CM_ "AUTOGENERATED FILE, DO NOT EDIT";

CM_ "rivian_mando_front_radar.dbc starts here";

VERSION ""

NS_ :

BS_:

BU_: XXX

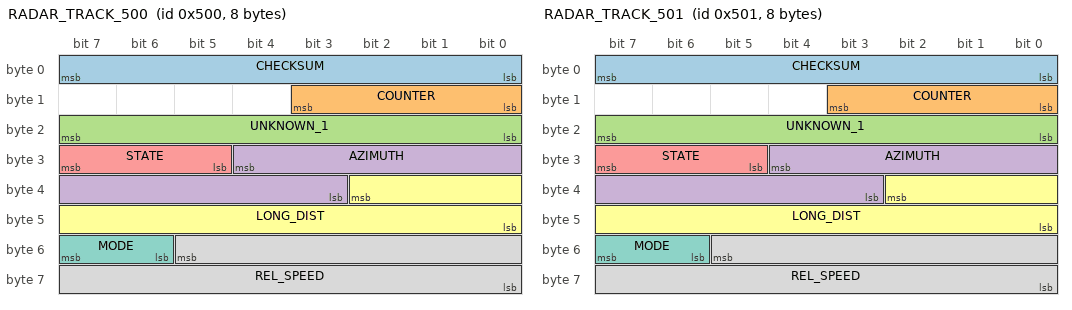
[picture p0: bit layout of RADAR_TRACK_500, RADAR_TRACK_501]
BO_ 1280 RADAR_TRACK_500: 8 RADAR
 SG_ CHECKSUM : 0|8@1+ (1,0) [0|255] "" XXX
 SG_ COUNTER : 11|4@0+ (1,0) [0|15] "" XXX
 SG_ UNKNOWN_1 : 23|8@0- (1,0) [-128|127] "" XXX
 SG_ AZIMUTH : 28|10@0- (0.1,0) [-51.2|51.1] "" XXX
 SG_ STATE : 31|3@0+ (1,0) [0|7] "" XXX
 SG_ LONG_DIST : 34|11@0+ (0.1,0) [0|204.7] "" XXX
 SG_ MODE : 55|2@0+ (1,0) [0|3] "" XXX
 SG_ REL_SPEED : 53|14@0- (0.01,0) [-81.92|81.92] "m/s" XXX

BO_ 1281 RADAR_TRACK_501: 8 RADAR
 SG_ CHECKSUM : 0|8@1+ (1,0) [0|255] "" XXX
 SG_ COUNTER : 11|4@0+ (1,0) [0|15] "" XXX
 SG_ UNKNOWN_1 : 23|8@0- (1,0) [-128|127] "" XXX
 SG_ AZIMUTH : 28|10@0- (0.1,0) [-51.2|51.1] "" XXX
 SG_ STATE : 31|3@0+ (1,0) [0|7] "" XXX
 SG_ LONG_DIST : 34|11@0+ (0.1,0) [0|204.7] "" XXX
 SG_ MODE : 55|2@0+ (1,0) [0|3] "" XXX
 SG_ REL_SPEED : 53|14@0- (0.01,0) [-81.92|81.92] "m/s" XXX

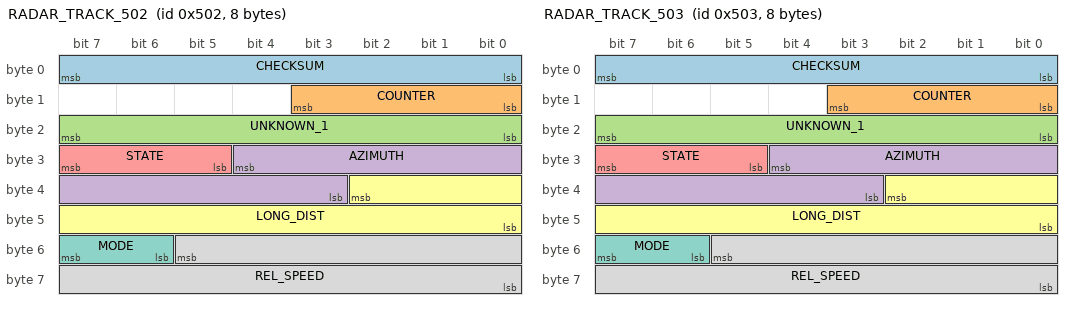
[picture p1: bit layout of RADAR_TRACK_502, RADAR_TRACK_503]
BO_ 1282 RADAR_TRACK_502: 8 RADAR
 SG_ CHECKSUM : 0|8@1+ (1,0) [0|255] "" XXX
 SG_ COUNTER : 11|4@0+ (1,0) [0|15] "" XXX
 SG_ UNKNOWN_1 : 23|8@0- (1,0) [-128|127] "" XXX
 SG_ AZIMUTH : 28|10@0- (0.1,0) [-51.2|51.1] "" XXX
 SG_ STATE : 31|3@0+ (1,0) [0|7] "" XXX
 SG_ LONG_DIST : 34|11@0+ (0.1,0) [0|204.7] "" XXX
 SG_ MODE : 55|2@0+ (1,0) [0|3] "" XXX
 SG_ REL_SPEED : 53|14@0- (0.01,0) [-81.92|81.92] "m/s" XXX

BO_ 1283 RADAR_TRACK_503: 8 RADAR
 SG_ CHECKSUM : 0|8@1+ (1,0) [0|255] "" XXX
 SG_ COUNTER : 11|4@0+ (1,0) [0|15] "" XXX
 SG_ UNKNOWN_1 : 23|8@0- (1,0) [-128|127] "" XXX
 SG_ AZIMUTH : 28|10@0- (0.1,0) [-51.2|51.1] "" XXX
 SG_ STATE : 31|3@0+ (1,0) [0|7] "" XXX
 SG_ LONG_DIST : 34|11@0+ (0.1,0) [0|204.7] "" XXX
 SG_ MODE : 55|2@0+ (1,0) [0|3] "" XXX
 SG_ REL_SPEED : 53|14@0- (0.01,0) [-81.92|81.92] "m/s" XXX

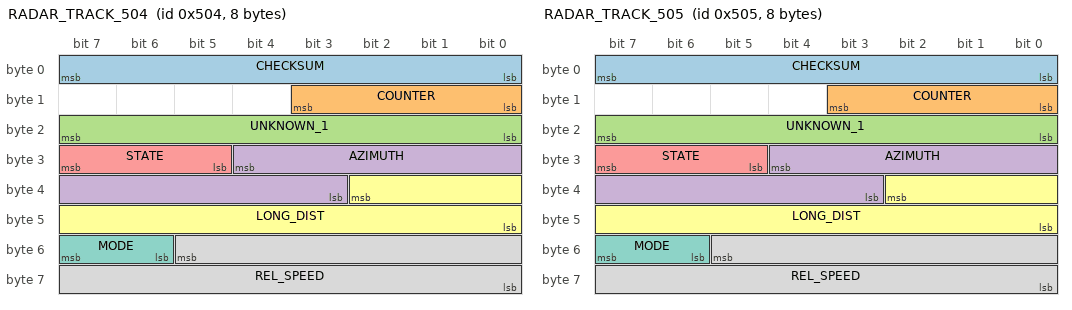
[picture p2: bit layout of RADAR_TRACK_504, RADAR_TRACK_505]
BO_ 1284 RADAR_TRACK_504: 8 RADAR
 SG_ CHECKSUM : 0|8@1+ (1,0) [0|255] "" XXX
 SG_ COUNTER : 11|4@0+ (1,0) [0|15] "" XXX
 SG_ UNKNOWN_1 : 23|8@0- (1,0) [-128|127] "" XXX
 SG_ AZIMUTH : 28|10@0- (0.1,0) [-51.2|51.1] "" XXX
 SG_ STATE : 31|3@0+ (1,0) [0|7] "" XXX
 SG_ LONG_DIST : 34|11@0+ (0.1,0) [0|204.7] "" XXX
 SG_ MODE : 55|2@0+ (1,0) [0|3] "" XXX
 SG_ REL_SPEED : 53|14@0- (0.01,0) [-81.92|81.92] "m/s" XXX

BO_ 1285 RADAR_TRACK_505: 8 RADAR
 SG_ CHECKSUM : 0|8@1+ (1,0) [0|255] "" XXX
 SG_ COUNTER : 11|4@0+ (1,0) [0|15] "" XXX
 SG_ UNKNOWN_1 : 23|8@0- (1,0) [-128|127] "" XXX
 SG_ AZIMUTH : 28|10@0- (0.1,0) [-51.2|51.1] "" XXX
 SG_ STATE : 31|3@0+ (1,0) [0|7] "" XXX
 SG_ LONG_DIST : 34|11@0+ (0.1,0) [0|204.7] "" XXX
 SG_ MODE : 55|2@0+ (1,0) [0|3] "" XXX
 SG_ REL_SPEED : 53|14@0- (0.01,0) [-81.92|81.92] "m/s" XXX

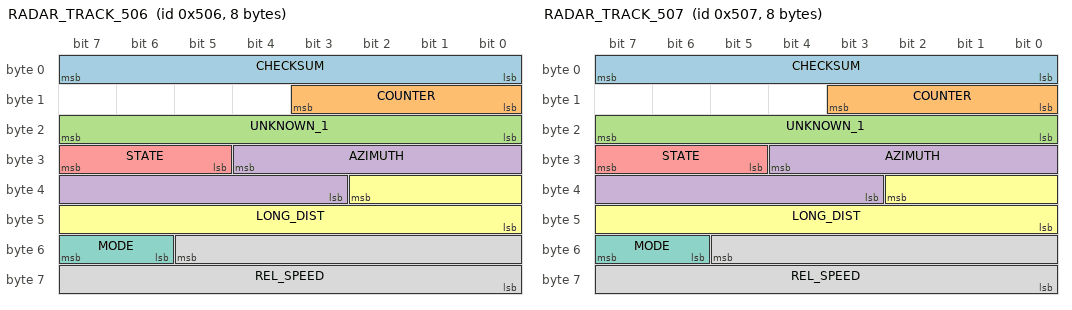
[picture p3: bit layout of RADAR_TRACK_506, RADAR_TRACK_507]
BO_ 1286 RADAR_TRACK_506: 8 RADAR
 SG_ CHECKSUM : 0|8@1+ (1,0) [0|255] "" XXX
 SG_ COUNTER : 11|4@0+ (1,0) [0|15] "" XXX
 SG_ UNKNOWN_1 : 23|8@0- (1,0) [-128|127] "" XXX
 SG_ AZIMUTH : 28|10@0- (0.1,0) [-51.2|51.1] "" XXX
 SG_ STATE : 31|3@0+ (1,0) [0|7] "" XXX
 SG_ LONG_DIST : 34|11@0+ (0.1,0) [0|204.7] "" XXX
 SG_ MODE : 55|2@0+ (1,0) [0|3] "" XXX
 SG_ REL_SPEED : 53|14@0- (0.01,0) [-81.92|81.92] "m/s" XXX

BO_ 1287 RADAR_TRACK_507: 8 RADAR
 SG_ CHECKSUM : 0|8@1+ (1,0) [0|255] "" XXX
 SG_ COUNTER : 11|4@0+ (1,0) [0|15] "" XXX
 SG_ UNKNOWN_1 : 23|8@0- (1,0) [-128|127] "" XXX
 SG_ AZIMUTH : 28|10@0- (0.1,0) [-51.2|51.1] "" XXX
 SG_ STATE : 31|3@0+ (1,0) [0|7] "" XXX
 SG_ LONG_DIST : 34|11@0+ (0.1,0) [0|204.7] "" XXX
 SG_ MODE : 55|2@0+ (1,0) [0|3] "" XXX
 SG_ REL_SPEED : 53|14@0- (0.01,0) [-81.92|81.92] "m/s" XXX

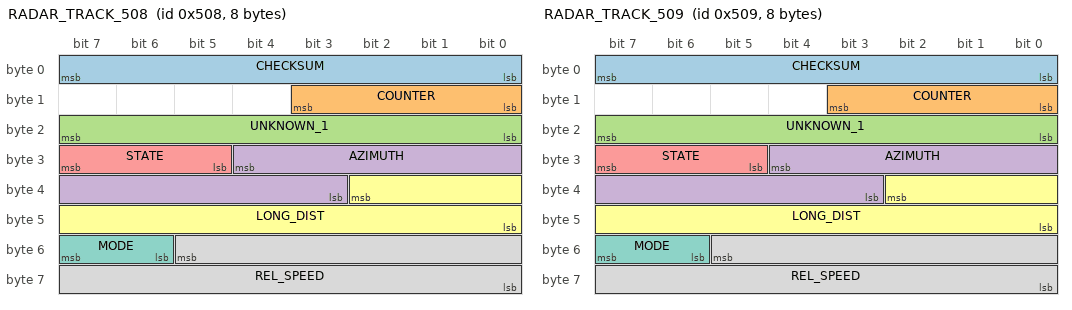
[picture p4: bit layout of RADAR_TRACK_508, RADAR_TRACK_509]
BO_ 1288 RADAR_TRACK_508: 8 RADAR
 SG_ CHECKSUM : 0|8@1+ (1,0) [0|255] "" XXX
 SG_ COUNTER : 11|4@0+ (1,0) [0|15] "" XXX
 SG_ UNKNOWN_1 : 23|8@0- (1,0) [-128|127] "" XXX
 SG_ AZIMUTH : 28|10@0- (0.1,0) [-51.2|51.1] "" XXX
 SG_ STATE : 31|3@0+ (1,0) [0|7] "" XXX
 SG_ LONG_DIST : 34|11@0+ (0.1,0) [0|204.7] "" XXX
 SG_ MODE : 55|2@0+ (1,0) [0|3] "" XXX
 SG_ REL_SPEED : 53|14@0- (0.01,0) [-81.92|81.92] "m/s" XXX

BO_ 1289 RADAR_TRACK_509: 8 RADAR
 SG_ CHECKSUM : 0|8@1+ (1,0) [0|255] "" XXX
 SG_ COUNTER : 11|4@0+ (1,0) [0|15] "" XXX
 SG_ UNKNOWN_1 : 23|8@0- (1,0) [-128|127] "" XXX
 SG_ AZIMUTH : 28|10@0- (0.1,0) [-51.2|51.1] "" XXX
 SG_ STATE : 31|3@0+ (1,0) [0|7] "" XXX
 SG_ LONG_DIST : 34|11@0+ (0.1,0) [0|204.7] "" XXX
 SG_ MODE : 55|2@0+ (1,0) [0|3] "" XXX
 SG_ REL_SPEED : 53|14@0- (0.01,0) [-81.92|81.92] "m/s" XXX

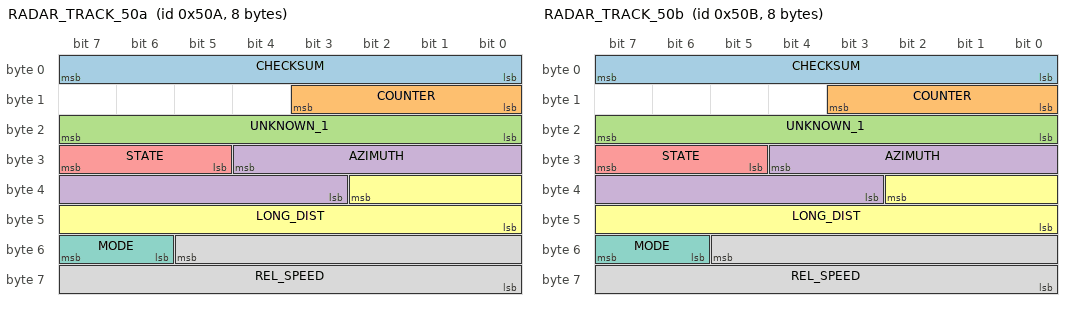
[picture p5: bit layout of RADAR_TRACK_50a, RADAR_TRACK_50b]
BO_ 1290 RADAR_TRACK_50a: 8 RADAR
 SG_ CHECKSUM : 0|8@1+ (1,0) [0|255] "" XXX
 SG_ COUNTER : 11|4@0+ (1,0) [0|15] "" XXX
 SG_ UNKNOWN_1 : 23|8@0- (1,0) [-128|127] "" XXX
 SG_ AZIMUTH : 28|10@0- (0.1,0) [-51.2|51.1] "" XXX
 SG_ STATE : 31|3@0+ (1,0) [0|7] "" XXX
 SG_ LONG_DIST : 34|11@0+ (0.1,0) [0|204.7] "" XXX
 SG_ MODE : 55|2@0+ (1,0) [0|3] "" XXX
 SG_ REL_SPEED : 53|14@0- (0.01,0) [-81.92|81.92] "m/s" XXX

BO_ 1291 RADAR_TRACK_50b: 8 RADAR
 SG_ CHECKSUM : 0|8@1+ (1,0) [0|255] "" XXX
 SG_ COUNTER : 11|4@0+ (1,0) [0|15] "" XXX
 SG_ UNKNOWN_1 : 23|8@0- (1,0) [-128|127] "" XXX
 SG_ AZIMUTH : 28|10@0- (0.1,0) [-51.2|51.1] "" XXX
 SG_ STATE : 31|3@0+ (1,0) [0|7] "" XXX
 SG_ LONG_DIST : 34|11@0+ (0.1,0) [0|204.7] "" XXX
 SG_ MODE : 55|2@0+ (1,0) [0|3] "" XXX
 SG_ REL_SPEED : 53|14@0- (0.01,0) [-81.92|81.92] "m/s" XXX

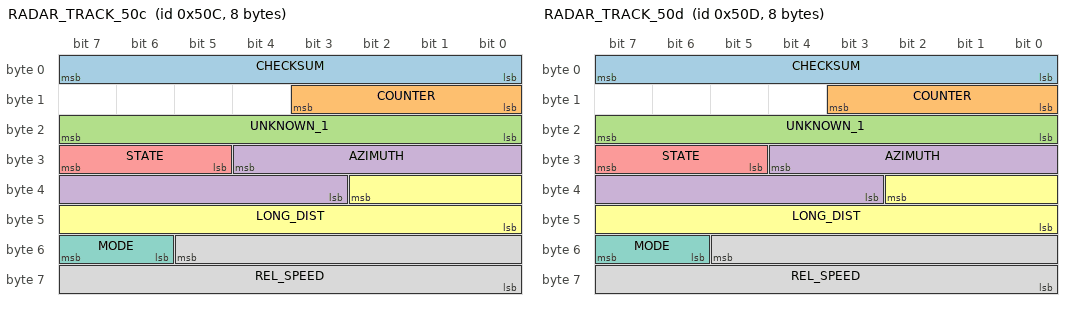
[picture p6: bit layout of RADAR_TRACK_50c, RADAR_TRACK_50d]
BO_ 1292 RADAR_TRACK_50c: 8 RADAR
 SG_ CHECKSUM : 0|8@1+ (1,0) [0|255] "" XXX
 SG_ COUNTER : 11|4@0+ (1,0) [0|15] "" XXX
 SG_ UNKNOWN_1 : 23|8@0- (1,0) [-128|127] "" XXX
 SG_ AZIMUTH : 28|10@0- (0.1,0) [-51.2|51.1] "" XXX
 SG_ STATE : 31|3@0+ (1,0) [0|7] "" XXX
 SG_ LONG_DIST : 34|11@0+ (0.1,0) [0|204.7] "" XXX
 SG_ MODE : 55|2@0+ (1,0) [0|3] "" XXX
 SG_ REL_SPEED : 53|14@0- (0.01,0) [-81.92|81.92] "m/s" XXX

BO_ 1293 RADAR_TRACK_50d: 8 RADAR
 SG_ CHECKSUM : 0|8@1+ (1,0) [0|255] "" XXX
 SG_ COUNTER : 11|4@0+ (1,0) [0|15] "" XXX
 SG_ UNKNOWN_1 : 23|8@0- (1,0) [-128|127] "" XXX
 SG_ AZIMUTH : 28|10@0- (0.1,0) [-51.2|51.1] "" XXX
 SG_ STATE : 31|3@0+ (1,0) [0|7] "" XXX
 SG_ LONG_DIST : 34|11@0+ (0.1,0) [0|204.7] "" XXX
 SG_ MODE : 55|2@0+ (1,0) [0|3] "" XXX
 SG_ REL_SPEED : 53|14@0- (0.01,0) [-81.92|81.92] "m/s" XXX

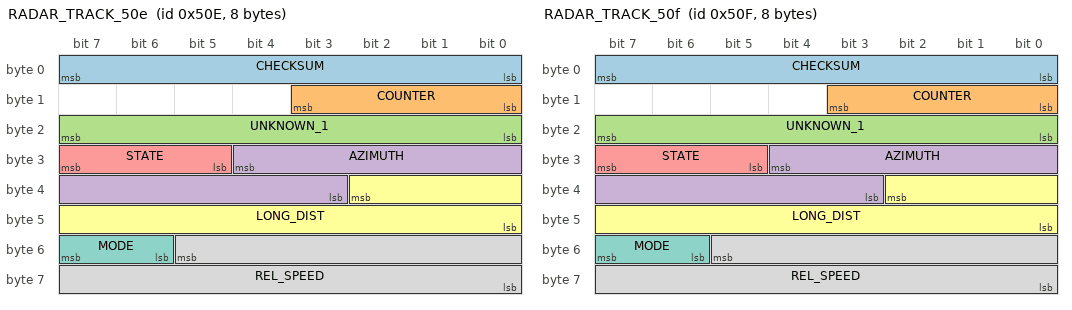
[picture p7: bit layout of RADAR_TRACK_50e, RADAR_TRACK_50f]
BO_ 1294 RADAR_TRACK_50e: 8 RADAR
 SG_ CHECKSUM : 0|8@1+ (1,0) [0|255] "" XXX
 SG_ COUNTER : 11|4@0+ (1,0) [0|15] "" XXX
 SG_ UNKNOWN_1 : 23|8@0- (1,0) [-128|127] "" XXX
 SG_ AZIMUTH : 28|10@0- (0.1,0) [-51.2|51.1] "" XXX
 SG_ STATE : 31|3@0+ (1,0) [0|7] "" XXX
 SG_ LONG_DIST : 34|11@0+ (0.1,0) [0|204.7] "" XXX
 SG_ MODE : 55|2@0+ (1,0) [0|3] "" XXX
 SG_ REL_SPEED : 53|14@0- (0.01,0) [-81.92|81.92] "m/s" XXX

BO_ 1295 RADAR_TRACK_50f: 8 RADAR
 SG_ CHECKSUM : 0|8@1+ (1,0) [0|255] "" XXX
 SG_ COUNTER : 11|4@0+ (1,0) [0|15] "" XXX
 SG_ UNKNOWN_1 : 23|8@0- (1,0) [-128|127] "" XXX
 SG_ AZIMUTH : 28|10@0- (0.1,0) [-51.2|51.1] "" XXX
 SG_ STATE : 31|3@0+ (1,0) [0|7] "" XXX
 SG_ LONG_DIST : 34|11@0+ (0.1,0) [0|204.7] "" XXX
 SG_ MODE : 55|2@0+ (1,0) [0|3] "" XXX
 SG_ REL_SPEED : 53|14@0- (0.01,0) [-81.92|81.92] "m/s" XXX

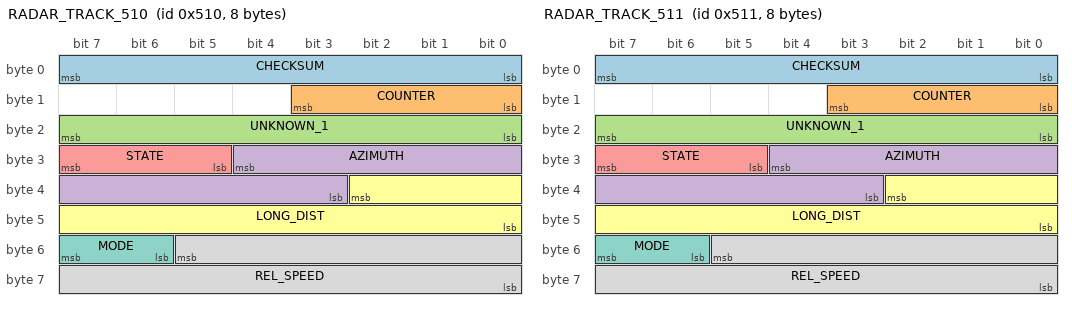
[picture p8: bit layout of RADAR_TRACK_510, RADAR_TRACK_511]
BO_ 1296 RADAR_TRACK_510: 8 RADAR
 SG_ CHECKSUM : 0|8@1+ (1,0) [0|255] "" XXX
 SG_ COUNTER : 11|4@0+ (1,0) [0|15] "" XXX
 SG_ UNKNOWN_1 : 23|8@0- (1,0) [-128|127] "" XXX
 SG_ AZIMUTH : 28|10@0- (0.1,0) [-51.2|51.1] "" XXX
 SG_ STATE : 31|3@0+ (1,0) [0|7] "" XXX
 SG_ LONG_DIST : 34|11@0+ (0.1,0) [0|204.7] "" XXX
 SG_ MODE : 55|2@0+ (1,0) [0|3] "" XXX
 SG_ REL_SPEED : 53|14@0- (0.01,0) [-81.92|81.92] "m/s" XXX

BO_ 1297 RADAR_TRACK_511: 8 RADAR
 SG_ CHECKSUM : 0|8@1+ (1,0) [0|255] "" XXX
 SG_ COUNTER : 11|4@0+ (1,0) [0|15] "" XXX
 SG_ UNKNOWN_1 : 23|8@0- (1,0) [-128|127] "" XXX
 SG_ AZIMUTH : 28|10@0- (0.1,0) [-51.2|51.1] "" XXX
 SG_ STATE : 31|3@0+ (1,0) [0|7] "" XXX
 SG_ LONG_DIST : 34|11@0+ (0.1,0) [0|204.7] "" XXX
 SG_ MODE : 55|2@0+ (1,0) [0|3] "" XXX
 SG_ REL_SPEED : 53|14@0- (0.01,0) [-81.92|81.92] "m/s" XXX

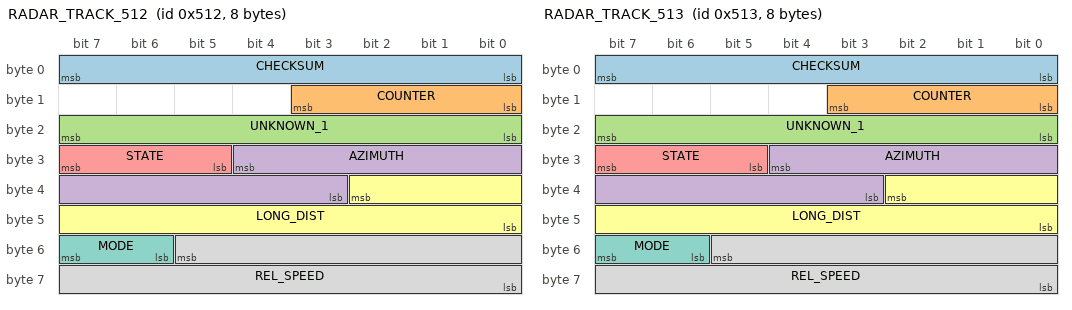
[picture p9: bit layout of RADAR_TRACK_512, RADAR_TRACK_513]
BO_ 1298 RADAR_TRACK_512: 8 RADAR
 SG_ CHECKSUM : 0|8@1+ (1,0) [0|255] "" XXX
 SG_ COUNTER : 11|4@0+ (1,0) [0|15] "" XXX
 SG_ UNKNOWN_1 : 23|8@0- (1,0) [-128|127] "" XXX
 SG_ AZIMUTH : 28|10@0- (0.1,0) [-51.2|51.1] "" XXX
 SG_ STATE : 31|3@0+ (1,0) [0|7] "" XXX
 SG_ LONG_DIST : 34|11@0+ (0.1,0) [0|204.7] "" XXX
 SG_ MODE : 55|2@0+ (1,0) [0|3] "" XXX
 SG_ REL_SPEED : 53|14@0- (0.01,0) [-81.92|81.92] "m/s" XXX

BO_ 1299 RADAR_TRACK_513: 8 RADAR
 SG_ CHECKSUM : 0|8@1+ (1,0) [0|255] "" XXX
 SG_ COUNTER : 11|4@0+ (1,0) [0|15] "" XXX
 SG_ UNKNOWN_1 : 23|8@0- (1,0) [-128|127] "" XXX
 SG_ AZIMUTH : 28|10@0- (0.1,0) [-51.2|51.1] "" XXX
 SG_ STATE : 31|3@0+ (1,0) [0|7] "" XXX
 SG_ LONG_DIST : 34|11@0+ (0.1,0) [0|204.7] "" XXX
 SG_ MODE : 55|2@0+ (1,0) [0|3] "" XXX
 SG_ REL_SPEED : 53|14@0- (0.01,0) [-81.92|81.92] "m/s" XXX

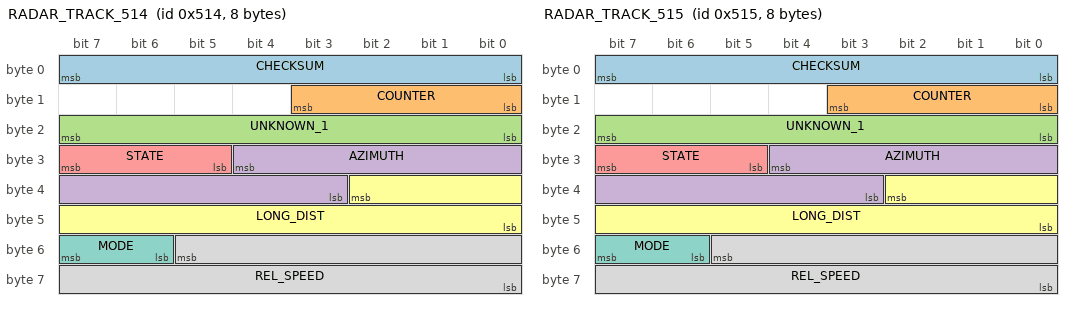
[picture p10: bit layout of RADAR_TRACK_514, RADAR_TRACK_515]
BO_ 1300 RADAR_TRACK_514: 8 RADAR
 SG_ CHECKSUM : 0|8@1+ (1,0) [0|255] "" XXX
 SG_ COUNTER : 11|4@0+ (1,0) [0|15] "" XXX
 SG_ UNKNOWN_1 : 23|8@0- (1,0) [-128|127] "" XXX
 SG_ AZIMUTH : 28|10@0- (0.1,0) [-51.2|51.1] "" XXX
 SG_ STATE : 31|3@0+ (1,0) [0|7] "" XXX
 SG_ LONG_DIST : 34|11@0+ (0.1,0) [0|204.7] "" XXX
 SG_ MODE : 55|2@0+ (1,0) [0|3] "" XXX
 SG_ REL_SPEED : 53|14@0- (0.01,0) [-81.92|81.92] "m/s" XXX

BO_ 1301 RADAR_TRACK_515: 8 RADAR
 SG_ CHECKSUM : 0|8@1+ (1,0) [0|255] "" XXX
 SG_ COUNTER : 11|4@0+ (1,0) [0|15] "" XXX
 SG_ UNKNOWN_1 : 23|8@0- (1,0) [-128|127] "" XXX
 SG_ AZIMUTH : 28|10@0- (0.1,0) [-51.2|51.1] "" XXX
 SG_ STATE : 31|3@0+ (1,0) [0|7] "" XXX
 SG_ LONG_DIST : 34|11@0+ (0.1,0) [0|204.7] "" XXX
 SG_ MODE : 55|2@0+ (1,0) [0|3] "" XXX
 SG_ REL_SPEED : 53|14@0- (0.01,0) [-81.92|81.92] "m/s" XXX

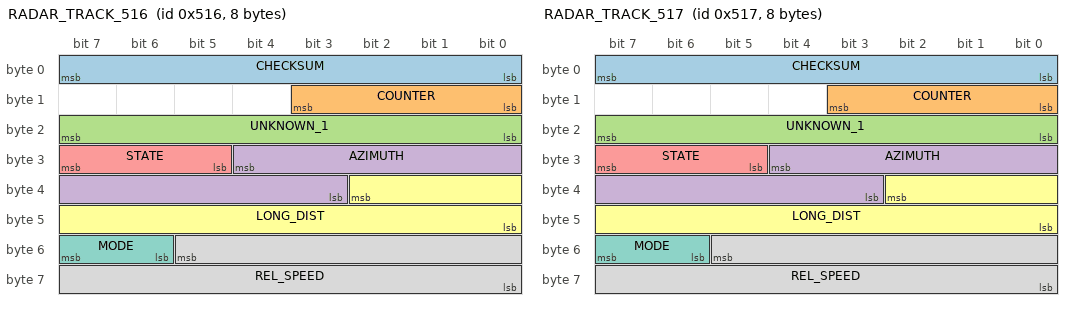
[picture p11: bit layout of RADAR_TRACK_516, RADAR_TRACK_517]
BO_ 1302 RADAR_TRACK_516: 8 RADAR
 SG_ CHECKSUM : 0|8@1+ (1,0) [0|255] "" XXX
 SG_ COUNTER : 11|4@0+ (1,0) [0|15] "" XXX
 SG_ UNKNOWN_1 : 23|8@0- (1,0) [-128|127] "" XXX
 SG_ AZIMUTH : 28|10@0- (0.1,0) [-51.2|51.1] "" XXX
 SG_ STATE : 31|3@0+ (1,0) [0|7] "" XXX
 SG_ LONG_DIST : 34|11@0+ (0.1,0) [0|204.7] "" XXX
 SG_ MODE : 55|2@0+ (1,0) [0|3] "" XXX
 SG_ REL_SPEED : 53|14@0- (0.01,0) [-81.92|81.92] "m/s" XXX

BO_ 1303 RADAR_TRACK_517: 8 RADAR
 SG_ CHECKSUM : 0|8@1+ (1,0) [0|255] "" XXX
 SG_ COUNTER : 11|4@0+ (1,0) [0|15] "" XXX
 SG_ UNKNOWN_1 : 23|8@0- (1,0) [-128|127] "" XXX
 SG_ AZIMUTH : 28|10@0- (0.1,0) [-51.2|51.1] "" XXX
 SG_ STATE : 31|3@0+ (1,0) [0|7] "" XXX
 SG_ LONG_DIST : 34|11@0+ (0.1,0) [0|204.7] "" XXX
 SG_ MODE : 55|2@0+ (1,0) [0|3] "" XXX
 SG_ REL_SPEED : 53|14@0- (0.01,0) [-81.92|81.92] "m/s" XXX

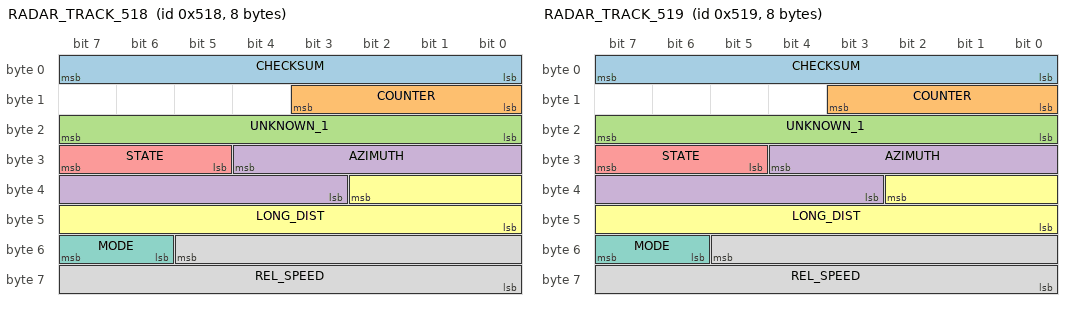
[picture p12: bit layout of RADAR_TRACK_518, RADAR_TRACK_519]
BO_ 1304 RADAR_TRACK_518: 8 RADAR
 SG_ CHECKSUM : 0|8@1+ (1,0) [0|255] "" XXX
 SG_ COUNTER : 11|4@0+ (1,0) [0|15] "" XXX
 SG_ UNKNOWN_1 : 23|8@0- (1,0) [-128|127] "" XXX
 SG_ AZIMUTH : 28|10@0- (0.1,0) [-51.2|51.1] "" XXX
 SG_ STATE : 31|3@0+ (1,0) [0|7] "" XXX
 SG_ LONG_DIST : 34|11@0+ (0.1,0) [0|204.7] "" XXX
 SG_ MODE : 55|2@0+ (1,0) [0|3] "" XXX
 SG_ REL_SPEED : 53|14@0- (0.01,0) [-81.92|81.92] "m/s" XXX

BO_ 1305 RADAR_TRACK_519: 8 RADAR
 SG_ CHECKSUM : 0|8@1+ (1,0) [0|255] "" XXX
 SG_ COUNTER : 11|4@0+ (1,0) [0|15] "" XXX
 SG_ UNKNOWN_1 : 23|8@0- (1,0) [-128|127] "" XXX
 SG_ AZIMUTH : 28|10@0- (0.1,0) [-51.2|51.1] "" XXX
 SG_ STATE : 31|3@0+ (1,0) [0|7] "" XXX
 SG_ LONG_DIST : 34|11@0+ (0.1,0) [0|204.7] "" XXX
 SG_ MODE : 55|2@0+ (1,0) [0|3] "" XXX
 SG_ REL_SPEED : 53|14@0- (0.01,0) [-81.92|81.92] "m/s" XXX

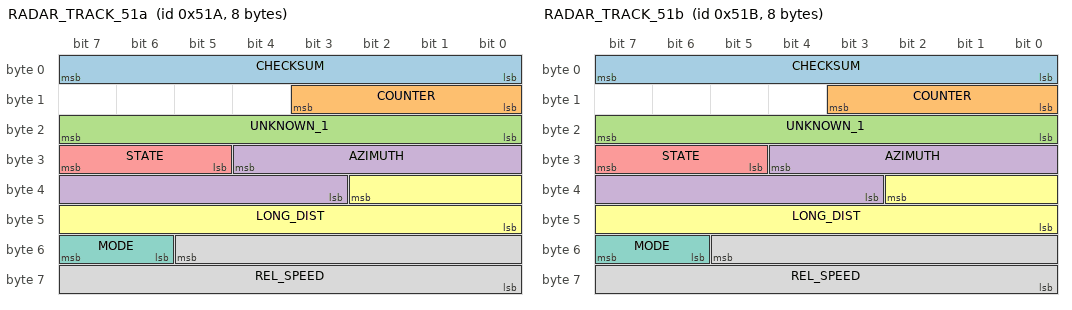
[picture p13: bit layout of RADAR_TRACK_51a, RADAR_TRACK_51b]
BO_ 1306 RADAR_TRACK_51a: 8 RADAR
 SG_ CHECKSUM : 0|8@1+ (1,0) [0|255] "" XXX
 SG_ COUNTER : 11|4@0+ (1,0) [0|15] "" XXX
 SG_ UNKNOWN_1 : 23|8@0- (1,0) [-128|127] "" XXX
 SG_ AZIMUTH : 28|10@0- (0.1,0) [-51.2|51.1] "" XXX
 SG_ STATE : 31|3@0+ (1,0) [0|7] "" XXX
 SG_ LONG_DIST : 34|11@0+ (0.1,0) [0|204.7] "" XXX
 SG_ MODE : 55|2@0+ (1,0) [0|3] "" XXX
 SG_ REL_SPEED : 53|14@0- (0.01,0) [-81.92|81.92] "m/s" XXX

BO_ 1307 RADAR_TRACK_51b: 8 RADAR
 SG_ CHECKSUM : 0|8@1+ (1,0) [0|255] "" XXX
 SG_ COUNTER : 11|4@0+ (1,0) [0|15] "" XXX
 SG_ UNKNOWN_1 : 23|8@0- (1,0) [-128|127] "" XXX
 SG_ AZIMUTH : 28|10@0- (0.1,0) [-51.2|51.1] "" XXX
 SG_ STATE : 31|3@0+ (1,0) [0|7] "" XXX
 SG_ LONG_DIST : 34|11@0+ (0.1,0) [0|204.7] "" XXX
 SG_ MODE : 55|2@0+ (1,0) [0|3] "" XXX
 SG_ REL_SPEED : 53|14@0- (0.01,0) [-81.92|81.92] "m/s" XXX

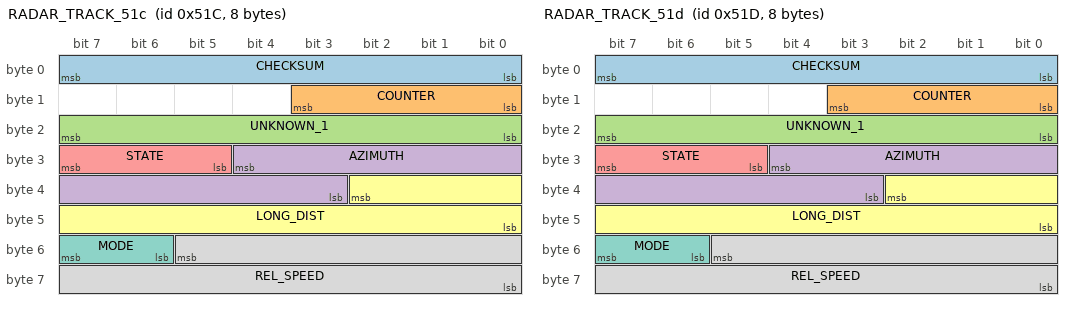
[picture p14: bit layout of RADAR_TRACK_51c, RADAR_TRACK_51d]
BO_ 1308 RADAR_TRACK_51c: 8 RADAR
 SG_ CHECKSUM : 0|8@1+ (1,0) [0|255] "" XXX
 SG_ COUNTER : 11|4@0+ (1,0) [0|15] "" XXX
 SG_ UNKNOWN_1 : 23|8@0- (1,0) [-128|127] "" XXX
 SG_ AZIMUTH : 28|10@0- (0.1,0) [-51.2|51.1] "" XXX
 SG_ STATE : 31|3@0+ (1,0) [0|7] "" XXX
 SG_ LONG_DIST : 34|11@0+ (0.1,0) [0|204.7] "" XXX
 SG_ MODE : 55|2@0+ (1,0) [0|3] "" XXX
 SG_ REL_SPEED : 53|14@0- (0.01,0) [-81.92|81.92] "m/s" XXX

BO_ 1309 RADAR_TRACK_51d: 8 RADAR
 SG_ CHECKSUM : 0|8@1+ (1,0) [0|255] "" XXX
 SG_ COUNTER : 11|4@0+ (1,0) [0|15] "" XXX
 SG_ UNKNOWN_1 : 23|8@0- (1,0) [-128|127] "" XXX
 SG_ AZIMUTH : 28|10@0- (0.1,0) [-51.2|51.1] "" XXX
 SG_ STATE : 31|3@0+ (1,0) [0|7] "" XXX
 SG_ LONG_DIST : 34|11@0+ (0.1,0) [0|204.7] "" XXX
 SG_ MODE : 55|2@0+ (1,0) [0|3] "" XXX
 SG_ REL_SPEED : 53|14@0- (0.01,0) [-81.92|81.92] "m/s" XXX

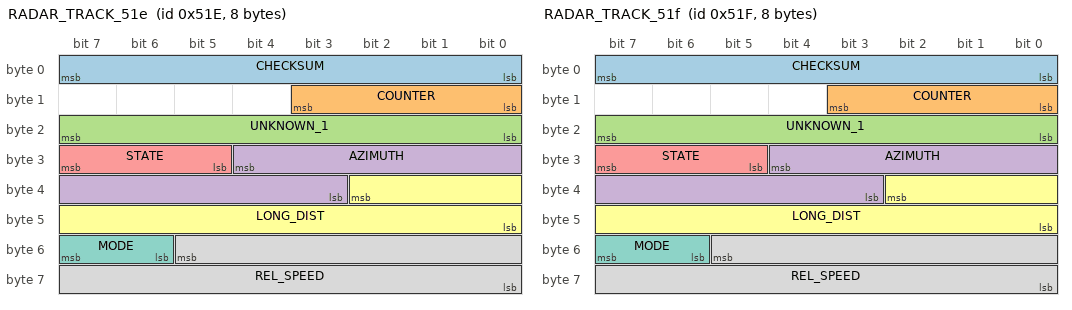
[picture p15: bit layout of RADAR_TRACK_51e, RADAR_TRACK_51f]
BO_ 1310 RADAR_TRACK_51e: 8 RADAR
 SG_ CHECKSUM : 0|8@1+ (1,0) [0|255] "" XXX
 SG_ COUNTER : 11|4@0+ (1,0) [0|15] "" XXX
 SG_ UNKNOWN_1 : 23|8@0- (1,0) [-128|127] "" XXX
 SG_ AZIMUTH : 28|10@0- (0.1,0) [-51.2|51.1] "" XXX
 SG_ STATE : 31|3@0+ (1,0) [0|7] "" XXX
 SG_ LONG_DIST : 34|11@0+ (0.1,0) [0|204.7] "" XXX
 SG_ MODE : 55|2@0+ (1,0) [0|3] "" XXX
 SG_ REL_SPEED : 53|14@0- (0.01,0) [-81.92|81.92] "m/s" XXX

BO_ 1311 RADAR_TRACK_51f: 8 RADAR
 SG_ CHECKSUM : 0|8@1+ (1,0) [0|255] "" XXX
 SG_ COUNTER : 11|4@0+ (1,0) [0|15] "" XXX
 SG_ UNKNOWN_1 : 23|8@0- (1,0) [-128|127] "" XXX
 SG_ AZIMUTH : 28|10@0- (0.1,0) [-51.2|51.1] "" XXX
 SG_ STATE : 31|3@0+ (1,0) [0|7] "" XXX
 SG_ LONG_DIST : 34|11@0+ (0.1,0) [0|204.7] "" XXX
 SG_ MODE : 55|2@0+ (1,0) [0|3] "" XXX
 SG_ REL_SPEED : 53|14@0- (0.01,0) [-81.92|81.92] "m/s" XXX

VAL_ 1280 STATE 0 "Empty" 1 "New" 2 "New_updated" 3 "Updated" 4 "Coasting" 7 "New_coasting" ;
VAL_ 1280 MODE 0 "None" 1 "SRR" 2 "LRR" 3 "SRR_and_LRR" ;

VAL_ 1281 STATE 0 "Empty" 1 "New" 2 "New_updated" 3 "Updated" 4 "Coasting" 7 "New_coasting" ;
VAL_ 1281 MODE 0 "None" 1 "SRR" 2 "LRR" 3 "SRR_and_LRR" ;

VAL_ 1282 STATE 0 "Empty" 1 "New" 2 "New_updated" 3 "Updated" 4 "Coasting" 7 "New_coasting" ;
VAL_ 1282 MODE 0 "None" 1 "SRR" 2 "LRR" 3 "SRR_and_LRR" ;

VAL_ 1283 STATE 0 "Empty" 1 "New" 2 "New_updated" 3 "Updated" 4 "Coasting" 7 "New_coasting" ;
VAL_ 1283 MODE 0 "None" 1 "SRR" 2 "LRR" 3 "SRR_and_LRR" ;

VAL_ 1284 STATE 0 "Empty" 1 "New" 2 "New_updated" 3 "Updated" 4 "Coasting" 7 "New_coasting" ;
VAL_ 1284 MODE 0 "None" 1 "SRR" 2 "LRR" 3 "SRR_and_LRR" ;

VAL_ 1285 STATE 0 "Empty" 1 "New" 2 "New_updated" 3 "Updated" 4 "Coasting" 7 "New_coasting" ;
VAL_ 1285 MODE 0 "None" 1 "SRR" 2 "LRR" 3 "SRR_and_LRR" ;

VAL_ 1286 STATE 0 "Empty" 1 "New" 2 "New_updated" 3 "Updated" 4 "Coasting" 7 "New_coasting" ;
VAL_ 1286 MODE 0 "None" 1 "SRR" 2 "LRR" 3 "SRR_and_LRR" ;

VAL_ 1287 STATE 0 "Empty" 1 "New" 2 "New_updated" 3 "Updated" 4 "Coasting" 7 "New_coasting" ;
VAL_ 1287 MODE 0 "None" 1 "SRR" 2 "LRR" 3 "SRR_and_LRR" ;

VAL_ 1288 STATE 0 "Empty" 1 "New" 2 "New_updated" 3 "Updated" 4 "Coasting" 7 "New_coasting" ;
VAL_ 1288 MODE 0 "None" 1 "SRR" 2 "LRR" 3 "SRR_and_LRR" ;

VAL_ 1289 STATE 0 "Empty" 1 "New" 2 "New_updated" 3 "Updated" 4 "Coasting" 7 "New_coasting" ;
VAL_ 1289 MODE 0 "None" 1 "SRR" 2 "LRR" 3 "SRR_and_LRR" ;

VAL_ 1290 STATE 0 "Empty" 1 "New" 2 "New_updated" 3 "Updated" 4 "Coasting" 7 "New_coasting" ;
VAL_ 1290 MODE 0 "None" 1 "SRR" 2 "LRR" 3 "SRR_and_LRR" ;

VAL_ 1291 STATE 0 "Empty" 1 "New" 2 "New_updated" 3 "Updated" 4 "Coasting" 7 "New_coasting" ;
VAL_ 1291 MODE 0 "None" 1 "SRR" 2 "LRR" 3 "SRR_and_LRR" ;

VAL_ 1292 STATE 0 "Empty" 1 "New" 2 "New_updated" 3 "Updated" 4 "Coasting" 7 "New_coasting" ;
VAL_ 1292 MODE 0 "None" 1 "SRR" 2 "LRR" 3 "SRR_and_LRR" ;

VAL_ 1293 STATE 0 "Empty" 1 "New" 2 "New_updated" 3 "Updated" 4 "Coasting" 7 "New_coasting" ;
VAL_ 1293 MODE 0 "None" 1 "SRR" 2 "LRR" 3 "SRR_and_LRR" ;

VAL_ 1294 STATE 0 "Empty" 1 "New" 2 "New_updated" 3 "Updated" 4 "Coasting" 7 "New_coasting" ;
VAL_ 1294 MODE 0 "None" 1 "SRR" 2 "LRR" 3 "SRR_and_LRR" ;

VAL_ 1295 STATE 0 "Empty" 1 "New" 2 "New_updated" 3 "Updated" 4 "Coasting" 7 "New_coasting" ;
VAL_ 1295 MODE 0 "None" 1 "SRR" 2 "LRR" 3 "SRR_and_LRR" ;

VAL_ 1296 STATE 0 "Empty" 1 "New" 2 "New_updated" 3 "Updated" 4 "Coasting" 7 "New_coasting" ;
VAL_ 1296 MODE 0 "None" 1 "SRR" 2 "LRR" 3 "SRR_and_LRR" ;

VAL_ 1297 STATE 0 "Empty" 1 "New" 2 "New_updated" 3 "Updated" 4 "Coasting" 7 "New_coasting" ;
VAL_ 1297 MODE 0 "None" 1 "SRR" 2 "LRR" 3 "SRR_and_LRR" ;

VAL_ 1298 STATE 0 "Empty" 1 "New" 2 "New_updated" 3 "Updated" 4 "Coasting" 7 "New_coasting" ;
VAL_ 1298 MODE 0 "None" 1 "SRR" 2 "LRR" 3 "SRR_and_LRR" ;

VAL_ 1299 STATE 0 "Empty" 1 "New" 2 "New_updated" 3 "Updated" 4 "Coasting" 7 "New_coasting" ;
VAL_ 1299 MODE 0 "None" 1 "SRR" 2 "LRR" 3 "SRR_and_LRR" ;

VAL_ 1300 STATE 0 "Empty" 1 "New" 2 "New_updated" 3 "Updated" 4 "Coasting" 7 "New_coasting" ;
VAL_ 1300 MODE 0 "None" 1 "SRR" 2 "LRR" 3 "SRR_and_LRR" ;

VAL_ 1301 STATE 0 "Empty" 1 "New" 2 "New_updated" 3 "Updated" 4 "Coasting" 7 "New_coasting" ;
VAL_ 1301 MODE 0 "None" 1 "SRR" 2 "LRR" 3 "SRR_and_LRR" ;

VAL_ 1302 STATE 0 "Empty" 1 "New" 2 "New_updated" 3 "Updated" 4 "Coasting" 7 "New_coasting" ;
VAL_ 1302 MODE 0 "None" 1 "SRR" 2 "LRR" 3 "SRR_and_LRR" ;

VAL_ 1303 STATE 0 "Empty" 1 "New" 2 "New_updated" 3 "Updated" 4 "Coasting" 7 "New_coasting" ;
VAL_ 1303 MODE 0 "None" 1 "SRR" 2 "LRR" 3 "SRR_and_LRR" ;

VAL_ 1304 STATE 0 "Empty" 1 "New" 2 "New_updated" 3 "Updated" 4 "Coasting" 7 "New_coasting" ;
VAL_ 1304 MODE 0 "None" 1 "SRR" 2 "LRR" 3 "SRR_and_LRR" ;

VAL_ 1305 STATE 0 "Empty" 1 "New" 2 "New_updated" 3 "Updated" 4 "Coasting" 7 "New_coasting" ;
VAL_ 1305 MODE 0 "None" 1 "SRR" 2 "LRR" 3 "SRR_and_LRR" ;

VAL_ 1306 STATE 0 "Empty" 1 "New" 2 "New_updated" 3 "Updated" 4 "Coasting" 7 "New_coasting" ;
VAL_ 1306 MODE 0 "None" 1 "SRR" 2 "LRR" 3 "SRR_and_LRR" ;

VAL_ 1307 STATE 0 "Empty" 1 "New" 2 "New_updated" 3 "Updated" 4 "Coasting" 7 "New_coasting" ;
VAL_ 1307 MODE 0 "None" 1 "SRR" 2 "LRR" 3 "SRR_and_LRR" ;

VAL_ 1308 STATE 0 "Empty" 1 "New" 2 "New_updated" 3 "Updated" 4 "Coasting" 7 "New_coasting" ;
VAL_ 1308 MODE 0 "None" 1 "SRR" 2 "LRR" 3 "SRR_and_LRR" ;

VAL_ 1309 STATE 0 "Empty" 1 "New" 2 "New_updated" 3 "Updated" 4 "Coasting" 7 "New_coasting" ;
VAL_ 1309 MODE 0 "None" 1 "SRR" 2 "LRR" 3 "SRR_and_LRR" ;

VAL_ 1310 STATE 0 "Empty" 1 "New" 2 "New_updated" 3 "Updated" 4 "Coasting" 7 "New_coasting" ;
VAL_ 1310 MODE 0 "None" 1 "SRR" 2 "LRR" 3 "SRR_and_LRR" ;

VAL_ 1311 STATE 0 "Empty" 1 "New" 2 "New_updated" 3 "Updated" 4 "Coasting" 7 "New_coasting" ;
VAL_ 1311 MODE 0 "None" 1 "SRR" 2 "LRR" 3 "SRR_and_LRR" ;
